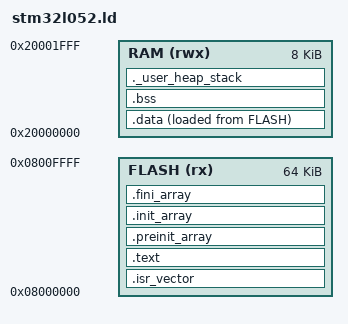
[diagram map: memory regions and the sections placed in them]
/**
 * @file stm32l052.ld
 * @brief Linker script for STM32L053C8 on STM32L0 Discovery board
 *
 * Memory map:
 *   FLASH : 0x08000000 - 0x0800FFFF (64 KB)
 *   RAM   : 0x20000000 - 0x20001FFF (8 KB)
 */

MEMORY
{
  FLASH (rx) : ORIGIN = 0x08000000, LENGTH = 64K
  RAM (rwx) : ORIGIN = 0x20000000, LENGTH = 8K
}

/* Define output sections */
SECTIONS
{
  /* The startup code goes first into FLASH */
  .isr_vector :
  {
    . = ALIGN(4);
    KEEP(*(.isr_vector)) /* Startup code */
    . = ALIGN(4);
  } >FLASH

  /* The program code and other data goes into FLASH */
  .text :
  {
    . = ALIGN(4);
    *(.text)           /* .text sections (code) */
    *(.text*)          /* .text* sections (code) */
    *(.rodata)         /* .rodata sections (constants, strings, etc.) */
    *(.rodata*)        /* .rodata* sections (constants, strings, etc.) */
    *(.glue_7)         /* glue provided by the linker */
    *(.glue_7t)        /* glue provided by the linker */

    . = ALIGN(4);
    _etext = .;        /* define a global symbols at end of code */
  } >FLASH

  /* Constant data into FLASH */
  .preinit_array :
  {
    PROVIDE_HIDDEN (__preinit_array_start = .);
    KEEP (*(.preinit_array*))
    PROVIDE_HIDDEN (__preinit_array_end = .);
  } >FLASH

  .init_array :
  {
    PROVIDE_HIDDEN (__init_array_start = .);
    KEEP (*(SORT(.init_array.*)))
    KEEP (*(.init_array*))
    PROVIDE_HIDDEN (__init_array_end = .);
  } >FLASH

  .fini_array :
  {
    PROVIDE_HIDDEN (__fini_array_start = .);
    KEEP (*(SORT(.fini_array.*)))
    KEEP (*(.fini_array*))
    PROVIDE_HIDDEN (__fini_array_end = .);
  } >FLASH

  /* Used by the startup code to initialize data */
  _sidata = LOADADDR(.data);

  /* Initialized data sections goes into RAM, load LMA copy after code */
  .data :
  {
    . = ALIGN(4);
    _sdata = .;        /* create a global symbol at data start */
    *(.data)           /* .data sections */
    *(.data*)          /* .data* sections */

    . = ALIGN(4);
    _edata = .;        /* define a global symbol at data end */
  } >RAM AT >FLASH

  /* Uninitialized data section */
  . = ALIGN(4);
  .bss :
  {
    /* This is used by the startup code to initialize the .bss section */
    _sbss = .;         /* define a global symbol at bss start */
    *(.bss)
    *(.bss*)
    *(COMMON)

    . = ALIGN(4);
    _ebss = .;         /* define a global symbol at bss end */
  } >RAM

  /* User_heap_stack section, used to check that there is enough RAM left */
  ._user_heap_stack :
  {
    . = ALIGN(8);
    PROVIDE ( end = . );
    PROVIDE ( _end = . );
    . = . + _Min_Heap_Size;
    . = . + _Min_Stack_Size;
    . = ALIGN(8);
  } >RAM

  /* Remove information from the standard object files */
  /DISCARD/ :
  {
    libc.a ( * )
    libm.a ( * )
    libgcc.a ( * )
  }

  .ARM.attributes 0 : { *(.ARM.attributes) }
}

/* Minimum heap and stack sizes */
_Min_Heap_Size = 0x200;      /* required amount of heap  */
_Min_Stack_Size = 0x400;     /* required amount of stack */
